AUTOSAR XML (schema 4-2-2)
package /Components
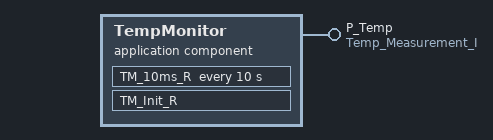
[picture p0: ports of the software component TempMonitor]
  application sw component type TempMonitor
    provide port P_Temp: provided-interface=Temp_Measurement_I
    behavior TempMonitor_InternalBehavior
      init event TM_Init_Event: start-on-event=TM_Init_R
      timing event TM_10ms_Event: start-on-event=TM_10ms_R, period=10
      runnable TM_Init_R
        data-send-points:
          access VA_TM_Init_Temp: accessed-variable=P_Temp.temp_cDegC
      runnable TM_10ms_R: minimum-start-interval=10
        data-send-points:
          access VA_TM_Periodic_Temp: accessed-variable=P_Temp.temp_cDegC
